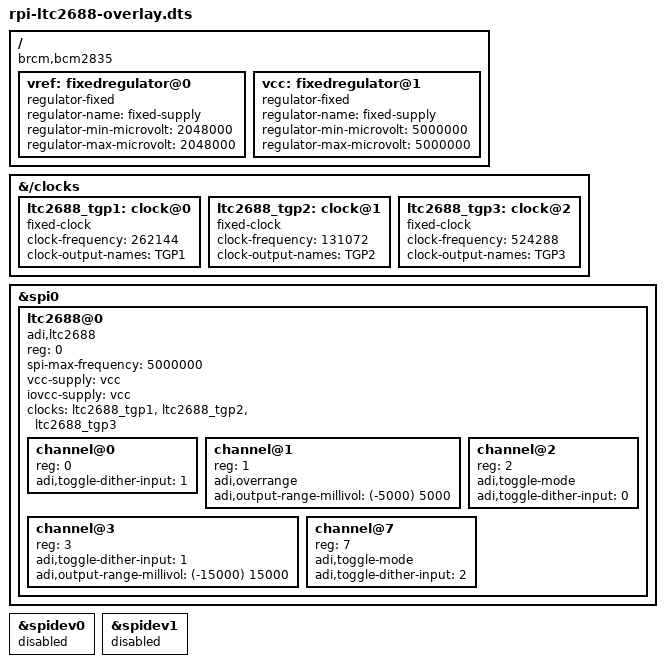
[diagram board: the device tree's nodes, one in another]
/dts-v1/;
/plugin/;

/ {
	compatible = "brcm,bcm2835", "brcm,bcm2708", "brcm,bcm2709";

	fragment@0 {
		target-path = "/";
		__overlay__ {

			vref: fixedregulator@0 {
				compatible = "regulator-fixed";
				regulator-name = "fixed-supply";
				regulator-min-microvolt = <2048000>;
				regulator-max-microvolt = <2048000>;
			};

			vcc: fixedregulator@1 {
				compatible = "regulator-fixed";
				regulator-name = "fixed-supply";
				regulator-min-microvolt = <5000000>;
				regulator-max-microvolt = <5000000>;
			};
		};
	};

	fragment@1 {
		target-path = "/clocks";
		__overlay__ {
			ltc2688_tgp1: clock@0 {
				compatible = "fixed-clock";
				#clock-cells = <0>;
				clock-frequency = <262144>;
				clock-output-names = "TGP1";
			};

			ltc2688_tgp2: clock@1 {
				compatible = "fixed-clock";
				#clock-cells = <0>;
				clock-frequency = <131072>;
				clock-output-names = "TGP2";
			};

			ltc2688_tgp3: clock@2 {
				compatible = "fixed-clock";
				#clock-cells = <0>;
				clock-frequency = <524288>;
				clock-output-names = "TGP3";
			};
		};
	};

	fragment@2 {
		target = <&spi0>;
		__overlay__ {
			#address-cells = <1>;
			#size-cells = <0>;
			status = "okay";

			ltc2688@0 {
				compatible = "adi,ltc2688";
				reg = <0>;
				spi-max-frequency = <5000000>;

				#address-cells = <1>;
				#size-cells = <0>;

				//vref-supply = <&vref>;
				vcc-supply = <&vcc>;
				iovcc-supply = <&vcc>;

				clocks = <&ltc2688_tgp1>, <&ltc2688_tgp2>, <&ltc2688_tgp3>;
				clock-names = "TGP1", "TGP2", "TGP3";

				channel@0 {
					reg = <0>;
					adi,toggle-dither-input = <1>;
				};

				channel@1 {
					reg = <1>;
                                        adi,overrange;
					adi,output-range-millivol = <(-5000) 5000>;
				};

				channel@2 {
					reg = <2>;
					adi,toggle-mode;
					adi,toggle-dither-input = <0>;
				};

				channel@3 {
					reg = <3>;
					adi,toggle-dither-input = <1>;
					// TODO: millivol need to be turned in microvolt to be a standard property
					adi,output-range-millivol = <(-15000) 15000>;
				};

				channel@7 {
					reg = <7>;
					adi,toggle-mode;
					adi,toggle-dither-input = <2>;
				};
			};
		};
	};

	fragment@4 {
		target = <&spidev0>;
		__overlay__ {
			status = "disabled";
		};
	};

	fragment@5 {
		target = <&spidev1>;
		__overlay__ {
			status = "disabled";
		};
	};
};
